# CEC1712H_B2_SX register map
Vendor: Microchip
Registers are 32-bit, read-write, reset 0x0 unless marked. A register's access mark holds for its fields unless they carry their own. Addresses are absolute, and some are shared; only a register's first bit layout is shown; [hi:lo] are bit positions; lines under a group give offsets from that group; {n}, {i} and the like mark numbered series.

## VBAT_RAM
{0x4000A800+4i} MEM{i} (i=0..15)

## WEEK
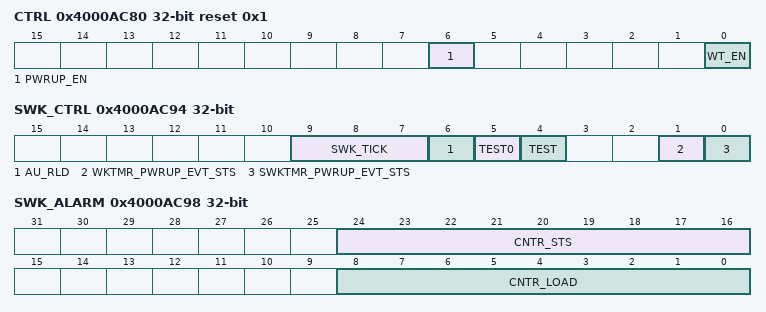
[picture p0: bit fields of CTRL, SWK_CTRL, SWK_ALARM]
0x4000AC80 CTRL reset 0x1
  [6] PWRUP_EN — This bit controls the state of the Power-Up Event Output and enables Week POWER-UP Event decoding in the VBAT-Powered Control Interface. 1=Power-Up Event Output Enabled. 0=Power-Up Event Output Disabled and Reset
  [0] WT_EN — The WT_ENABLE bit is used to start and stop the Week Alarm Counter Register and the Clock Divider Register. The value in the Counter Register is held when the WT_ENABLE bit is not asserted (0) and the count is resumed from the last value when the bit is asserted (1). The 15-Bit Clock Divider is reset to 00h and the Week Alarm Interface is in its lowest power consumption state when the WT_ENABLE bit is not asserted.
0x4000AC84 ALARM_CNT
  [27:0] WK_CNTR — While the WT_ENABLE bit is 1, this register is incremented at a 1 Hz rate. Writes of this register may require one second to take effect. Reads return the current state of the register. Reads and writes complete independently of the state of WT_ENABLE.
0x4000AC88 TMR_COMP reset 0xFFFFFFF
  [27:0] WK_COMP — A Week Alarm Interrupt and a Week Alarm Power-Up Event are asserted when the Week Alarm Counter Register is greater than or equal to the contents of this register. Reads and writes complete independently of the state of WT_ENABLE.
0x4000AC8C CLKDIV
  [14:0] DIV — Reads of this register return the current state of the Week Timer 15- bit clock divider.
0x4000AC90 SS_INTR_SEL
  [3:0] SPISR — This field determines the rate at which Sub-Second interrupt events are generated.
0x4000AC94 SWK_CTRL ro
  [9:7] SWK_TICK — This field selects the clock source for the Sub-Week Counter.
  [6] AU_RLD — 1= No reload occurs when the Sub-Week Counter expires. 0= Reloads the SUBWEEK_COUNTER_LOAD field into the Sub- Week Counter when the counter expires.
  [5] TEST0 — Test
  [4] TEST
  [1] WKTMR_PWRUP_EVT_STS — This bit is set to 1 when the Week Alarm Counter Register is greater than or equal the contents of the Week Timer Compare. Register and the POWERUP_EN is 1. Writes of 1 clear this bit. Writes of 0 have no effect. Note: This bit does not have to be cleared to remove a Week Timer Power-Up Event.
  [0] SWKTMR_PWRUP_EVT_STS — This bit is set to 1 when the Sub-Week Alarm Counter Register decrements from 1 to 0 and the POWERUP_EN is 1. Writes of 1 clear this bit. Writes of 0 have no effect. Note: This bit MUST be cleared to remove a Sub-Week Timer Power-Up Event.
0x4000AC98 SWK_ALARM ro
  [24:16] CNTR_STS — Reads of this register return the current state of the 9-bit Sub-Week Alarm counter.
  [8:0] CNTR_LOAD — Writes with a non-zero value to this field reload the 9-bit Sub-Week Alarm counter. Writes of 0 disable the counter. If the Sub-Week Alarm counter decrements to 0 and the AUTO_RELOAD bit is set, the value in this field is automatically loaded into the Sub-Week Alarm counter.

## ECIA
{0x4000DF60+0x14*i} SRC{i} (i=8..26)
{0x4000DF64+0x14*i} EN_SET{i} (i=8..26)
{0x4000DF68+0x14*i} RESULT{i} ro (i=8..26)
{0x4000DF6C+0x14*i} EN_CLR{i} (i=8..26)
0x4000E200 BLK_EN_SET
  [30:0] VTOR_EN_SET — Each GIRQx bit can be individually enabled to assert an interrupt event. Reads always return the current value of the internal GIRQX_ENABLE bit. The state of the GIRQX_ENABLE bit is determined by the corresponding GIRQX_ENABLE_SET bit and the GIRQX_ENABLE_CLEAR bit. (0=disabled, 1=enabled) (R/WS). 1=Interrupts in the GIRQx Source Register may be enabled. 0=No effect.
0x4000E204 BLK_EN_CLR
  [30:0] VTOR_EN_CLR — Each GIRQx bit can be individually disabled to inhibit an interrupt event. Reads always return the current value of the internal GIRQX_ENABLE bit. The state of the GIRQX_ENABLE bit is determined by the corresponding GIRQX_ENABLE_SET bit and the GIRQX_ENABLE_CLEAR bit. (0=disabled, 1=enabled) (R/WC). 1=All interrupts in the GIRQx Source Register are disabled. 0=No effect.
0x4000E208 BLK_IRQ_VTOR ro
  [24:0] VTOR — Each bit in this field reports the status of the group GIRQ interrupt assertion to the NVIC. If the GIRQx interrupt is disabled as a group, by the Block Enable Clear Register, then the corresponding bit will be '0'b and no interrupt will be asserted.
